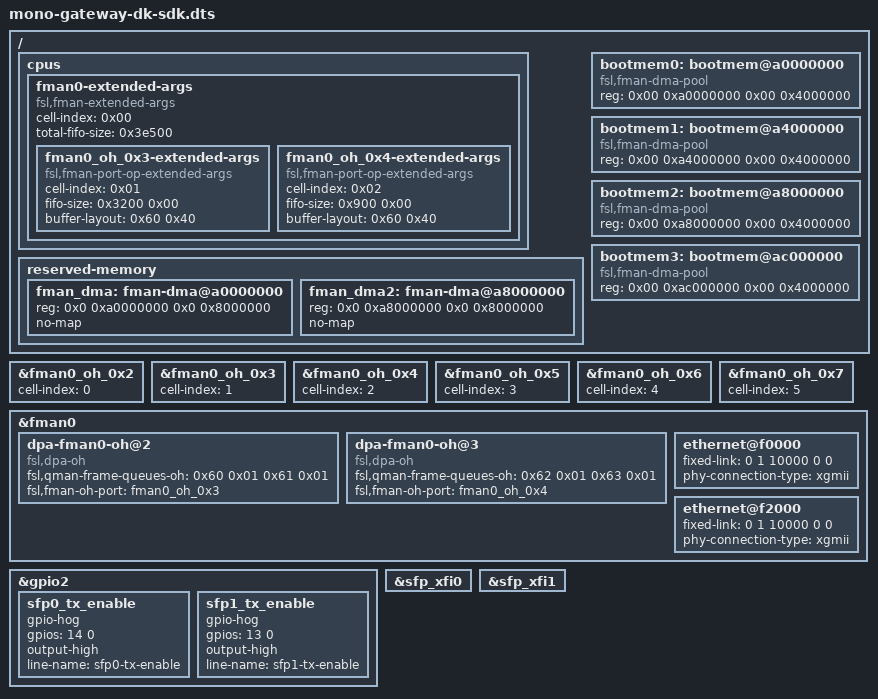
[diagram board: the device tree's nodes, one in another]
// SPDX-License-Identifier: (GPL-2.0+ OR MIT)
/*
 * Mono Gateway DK — SDK device tree (VyOS variant)
 *
 * Includes the mainline board DTS plus SDK portal overlays (cell-index
 * on BMan/QMan portals), OH port bindings for CDX IPsec, FMan extended-args
 * for per-port FIFO sizing, and 10G fixed-link overrides for SFP+ cages.
 *
 * Source: we-are-mono/OpenWRT-ASK (target/linux/layerscape/files/)
 * Adapted for VyOS: bootmem nodes removed (conflict with initramfs),
 * fman0-extended-args retained (config only, no memory reservation),
 * OH port bindings + 10G fixed-link overrides added.
 */

#include "mono-gateway-dk.dts"
#include "qoriq-qman-portals-sdk.dtsi"
#include "qoriq-bman-portals-sdk.dtsi"

/*
 * Fix OH port cell-index values.
 *
 * qoriq-fman3-0.dtsi sets cell-index 2-7 on ports 82000-87000, but the
 * SDK FMan port driver requires cell-index < FM_MAX_NUM_OF_OH_PORTS (6).
 * Override to match qoriq-fman3-0-6oh.dtsi: 0-5.
 */
&fman0_oh_0x2 { /delete-property/ cell-index; cell-index = <0>; };
&fman0_oh_0x3 { /delete-property/ cell-index; cell-index = <1>; };
&fman0_oh_0x4 { /delete-property/ cell-index; cell-index = <2>; };
&fman0_oh_0x5 { /delete-property/ cell-index; cell-index = <3>; };
&fman0_oh_0x6 { /delete-property/ cell-index; cell-index = <4>; };
&fman0_oh_0x7 { /delete-property/ cell-index; cell-index = <5>; };

/*
 * FMan offline-parsing (OH) port bindings — required for cdx IPsec offload.
 *
 * Two OH ports (port@83000/IPsec and port@84000/WiFi) are bound to specific
 * QMan frame queues for CDX/IPsec packet re-injection. The cdx module's
 * devoh.c queries these via oh_port_driver_get_port_info().
 *
 * Matching OpenWRT mono-gateway-dk-sdk.dts lines 314-325.
 */
&fman0 {
	dpa-fman0-oh@2 {
		compatible = "fsl,dpa-oh";
		fsl,qman-frame-queues-oh = <0x60 0x01 0x61 0x01>;
		fsl,fman-oh-port = <&fman0_oh_0x3>;
	};

	dpa-fman0-oh@3 {
		compatible = "fsl,dpa-oh";
		fsl,qman-frame-queues-oh = <0x62 0x01 0x63 0x01>;
		fsl,fman-oh-port = <&fman0_oh_0x4>;
	};
};

/*
 * FMan extended-args — per-port FIFO sizing for the SDK FMan driver.
 *
 * This is a config descriptor under /cpus/ (NOT a memory reservation).
 * It tells the SDK FMan driver the FIFO sizes for OH ports used by CDX.
 * total-fifo-size = 0x3e500 (254,272 bytes).
 *
 * Without this, alloc_offline_port() fails with "no free of ports"
 * because the FMan driver doesn't know how to size the OH port FIFOs.
 *
 * Matching OpenWRT mono-gateway-dk-sdk.dts lines 24-48 (safe subset).
 * bootmem0/bootmem1 nodes are NOT included — they conflict with VyOS
 * initramfs boot (U-Boot loads initrd to the same region).
 */
/ {
	cpus {
		fman0-extended-args {
		cell-index = <0x00>;
		compatible = "fsl,fman-extended-args";
		total-fifo-size = <0x3e500>;

		/*
		 * OH port extended-args — cell-index matches the SDK
		 * override values (port@83000=1, port@84000=2)
		 */
		fman0_oh_0x3-extended-args {
			cell-index = <0x01>;
			compatible = "fsl,fman-port-op-extended-args";
			fifo-size = <0x3200 0x00>;   /* 12,800 bytes for IPsec */
			buffer-layout = <0x60 0x40>;
		};

		fman0_oh_0x4-extended-args {
			cell-index = <0x02>;
			compatible = "fsl,fman-port-op-extended-args";
			fifo-size = <0x900 0x00>;    /* 2,304 bytes for WiFi */
			buffer-layout = <0x60 0x40>;
		};
	};
};
}; /* / (root node re-entry close) */

/* ── FMan DMA memory reservations ────────────────────────────────────────
 * The SDK fsl_fman/fsl_mac driver needs contiguous DMA regions for 10G
 * port buffer descriptors. OpenWRT achieves this via custom bootmem{} DTS
 * nodes, but those conflict with the VyOS initramfs load address.
 *
 * Using the standard /reserved-memory binding avoids that: the kernel
 * carves these regions out during early init, before initramfs is
 * unpacked. The SDK driver still uses its own bootmem parser, but these
 * no-map nodes ensure the regions are never handed out to other users.
 *
 * 320 MB total: 0xa0000000–0xb3ffffff (same range as OpenWRT bootmem).
 */
/ {
    reserved-memory {
        /* FMan DMA regions — carved out before initramfs loads.
         * The SDK fsl_mac driver parses bootmem nodes for 10G port
         * DMA descriptors. 256 MB at 0xa0000000–0xafffffff,
         * stopping before ramoops at 0xb0000000. */
        fman_dma: fman-dma@a0000000 {
            reg = <0x0 0xa0000000 0x0 0x8000000>;   /* 128 MB */
            no-map;
        };
        fman_dma2: fman-dma@a8000000 {
            reg = <0x0 0xa8000000 0x0 0x8000000>;   /* 128 MB */
            no-map;
        };
    };

    /* SDK driver-compatible bootmem nodes inside reserved-memory.
     * reg format matches OpenWRT's two-tuple, split to avoid the
     * kernel ignoring a second region. */
    bootmem0: bootmem@a0000000 {
        compatible = "fsl,fman-dma-pool";
        reg = <0x00 0xa0000000 0x00 0x4000000>;
    };
    bootmem1: bootmem@a4000000 {
        compatible = "fsl,fman-dma-pool";
        reg = <0x00 0xa4000000 0x00 0x4000000>;
    };
    bootmem2: bootmem@a8000000 {
        compatible = "fsl,fman-dma-pool";
        reg = <0x00 0xa8000000 0x00 0x4000000>;
    };
    bootmem3: bootmem@ac000000 {
        compatible = "fsl,fman-dma-pool";
        reg = <0x00 0xac000000 0x00 0x4000000>;
    };
};

/*
 * 10G MAC fixed-link overrides (matching OpenWRT SDK DTS).
 *
 * The SDK fsl_mac driver does NOT support managed="in-band-status" or
 * sfp=<...> — those are mainline DPAA bindings. Without explicit fixed-link
 * the SDK driver falls through to a broken swphy emulation (10G isn't
 * representable in Clause 22 MII registers). Set fixed-link=10000/Full
 * so the SDK driver skips the swphy path and initialises the serdes
 * directly for 10GBASE-R/XGMII.
 */
&fman0 {
	ethernet@f0000 {
		/delete-property/ managed;
		/delete-property/ sfp;
		fixed-link = <0 1 10000 0 0>;
		phy-connection-type = "xgmii";
	};

	ethernet@f2000 {
		/delete-property/ managed;
		/delete-property/ sfp;
		fixed-link = <0 1 10000 0 0>;
		phy-connection-type = "xgmii";
	};
};

/*
 * GPIO hogs: force TX_DISABLE HIGH (TX enabled) at boot.
 * We remove tx-disable-gpios from the SFP nodes below so the SFP driver
 * doesn't request these GPIOs (no conflict). The SFP driver still binds,
 * reads the SFP EEPROM, and configures the serdes rate via the MAC.
 * TX is always enabled because the GPIO hogs hold pins 13+14 HIGH.
 */
&gpio2 {
    sfp0_tx_enable {
        gpio-hog;
        gpios = <14 0>;  /* pin 14 = sfp-xfi0 (eth3), output HIGH → TX on */
        output-high;
        line-name = "sfp0-tx-enable";
    };
    sfp1_tx_enable {
        gpio-hog;
        gpios = <13 0>;  /* pin 13 = sfp-xfi1 (eth4), output HIGH → TX on */
        output-high;
        line-name = "sfp1-tx-enable";
    };
};

/* SFP nodes: keep enabled (EEPROM/serdes config) but remove tx-disable-gpios */
&sfp_xfi0 {
    /delete-property/ tx-disable-gpios;
};

&sfp_xfi1 {
    /delete-property/ tx-disable-gpios;
};
